# ESP32S31_RADIO register map
Vendor: Espressif; Series: ESP32-S31; File version: 3.52
Registers are 32-bit, read-write, no defined reset value unless marked. A register's access mark holds for its fields unless they carry their own. Offsets are from the block's base; [hi:lo] are bit positions; lines under a group give offsets from that group; {n}, {i} and the like mark numbered series.

## WIFI_MAC_TX_QUEUE_CONTROL — Four ascending physical banks represent logical EDCA queues 3,2,1,0.
Base 0x20104D34
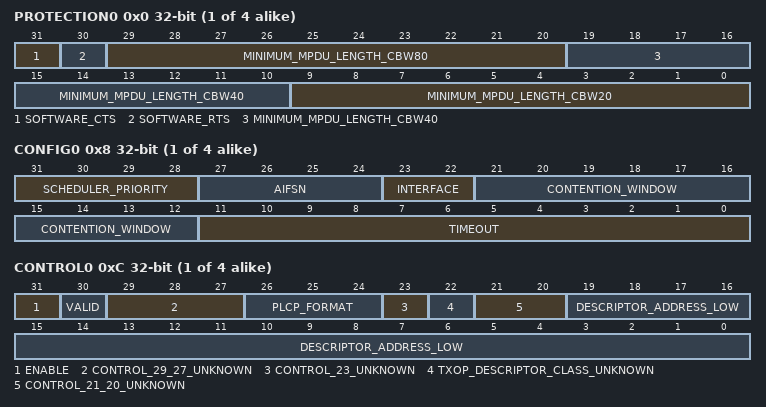
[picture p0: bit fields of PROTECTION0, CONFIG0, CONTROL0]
{0x0+0x10*i} PROTECTION{i} (i=0..3) — Canonical WDEVTXQ_CONF2. Complete dbg_read_txq_conf2 names the three ten-bit lanes TXQ_MIN_MPDU_LEN for CBW20, CBW40 and CBW80, followed by SW_RTS and SW_CTS. For HT, complete mac_tx_set_htsig copies peer state offset 0x82 into all three lanes; complete rcUpdateAMPDUParam derives that value from the HT A-MPDU minimum MPDU start-spacing code. For HE, complete ppCalDeliNum stores the rate/GI/DCM/density-specific minimum subframe byte count at descriptor offset 0x28 and complete mac_tx_set_hesig copies that halfword into all three lanes. The HE init suffix clears the same SW_RTS/SW_CTS pair, not an independent register. A coherent hardware-owned vendor HT queue contained 0x0280a028, exactly three copies of negotiated value 40. Open HE20 MCS9 HIL with 16-us density proved value 230: fixed snapshot 0x31 lost all 32 MPDUs, while three copies of 230 received a full first-attempt BlockAck with 43 empty delimiters per non-final subframe. The descriptor-count RMWs target the separate queue-vector word at 0x20105504-q*0x7c.
  [31] SOFTWARE_CTS — Complete dbg_read_txq_conf2 names bit 31 SW_CTS.
  [30] SOFTWARE_RTS — Complete dbg_read_txq_conf2 names bit 30 SW_RTS.
  [29:20] MINIMUM_MPDU_LENGTH_CBW80 — Third copy of the HT peer-derived or HE rate/density-derived minimum MPDU/subframe value.
  [19:10] MINIMUM_MPDU_LENGTH_CBW40 — Second copy of the HT peer-derived or HE rate/density-derived minimum MPDU/subframe value.
  [9:0] MINIMUM_MPDU_LENGTH_CBW20 — First copy of the HT peer-derived or HE rate/density-derived minimum MPDU/subframe value.
{0x8+0x10*i} CONFIG{i} (i=0..3) — Timeout, contention window, interface, AIFSN and scheduler-priority fields configured as distinct recovered RMW edges. Scheduler priority is not the original packet PTI retained in the vector bank.
  [31:28] SCHEDULER_PRIORITY — Complete mac_tx_set_pti writes the unsigned minimum of packet PTI and coexistence event-one PTI here. This scheduler value is independent of the four original packet-PTI lanes in the vector bank; for Authentication and Association both values resolve to one. Open HIL read scheduler one in five reset-to-connect repetitions.
  [27:24] AIFSN
  [23:22] INTERFACE
  [21:12] CONTENTION_WINDOW
  [11:0] TIMEOUT
{0xC+0x10*i} CONTROL{i} (i=0..3) — Descriptor address and PLCP0 format image in low 30 bits; VALID bit 30 and ENABLE bit 31 publish hardware ownership.
  [31] ENABLE
  [30] VALID
  [29:27] CONTROL_29_27_UNKNOWN — Remaining low control bits before ownership publication.
  [26:24] PLCP_FORMAT — Three-bit format selector derived by complete mac_tx_set_plcp0 from vendor descriptor flags. For the bounded plain legacy roots, ppTxProtoProc maps the address-one I/G bit to descriptor flag 0x2: group traffic retains format zero, while an ordinary individual-address descriptor with zero flags selects format one. Exact vendor callback images select format one for both non-A-MPDU HT20 MCS0 and HE20 MCS0 DCM S-MPDU frames; the owned open paths receive ACK at the same format. Independently captured HT and HE A-MPDU images select aggregate format two or five respectively. Format three has an instruction-exact descriptor branch but its higher-level meaning remains open. A legacy-only single-variable A/B temporarily correlated format one with status five and format zero with one authentication response, but format-zero repetitions failed; that experiment is retained as evidence that completion status alone is not a protocol-success oracle, not as an override of the complete blob mapping.
  [23] CONTROL_23_UNKNOWN — Recovered PLCP0 control image; mac_tx_set_plcp0 initializes this bit to zero for the ordinary direct legacy path.
  [22] TXOP_DESCRIPTOR_CLASS_UNKNOWN — Complete pp.o ppTxFragmentProc reaches its common legacy setup at offsets 0x8e..0xa8 from the CCMP selector-three branch at 0x22a and sets descriptor bit seven. Complete hal_mac_tx.o mac_tx_set_txop_q offsets 0x86..0xaa then sets this queue-control bit exactly when descriptor flag bits 7:6 equal binary 10 and clears it otherwise. Thus the bounded ordinary individual/group CCMP path sets this bit after mac_tx_set_plcp0. A 2026-07-29 open HIL A/B clearing the bit increased raw ACK timeouts from the prior roughly 28 percent to 1395/2325 attempts (60 percent), so the exact set mapping is retained while the electrical meaning remains unknown.
  [21:20] CONTROL_21_20_UNKNOWN — Recovered PLCP0 control image; mac_tx_set_plcp0 initializes these two bits to binary 10 for the ordinary direct legacy path.
  [19:0] DESCRIPTOR_ADDRESS_LOW — Low twenty bits of the owned TX descriptor address; the DMA window supplies the high address bits.
